# NUC029AN_v1 register map
File version: 1.0
Registers are 32-bit, read-write, reset 0x0 unless marked. A register's access mark holds for its fields unless they carry their own. Offsets are from the block's base; [hi:lo] are bit positions; {n}, {i} and the like mark numbered series; 'fields as' and 'values as' point back to an identical list.

## CLK — CLK Register Map
Base 0x50000200
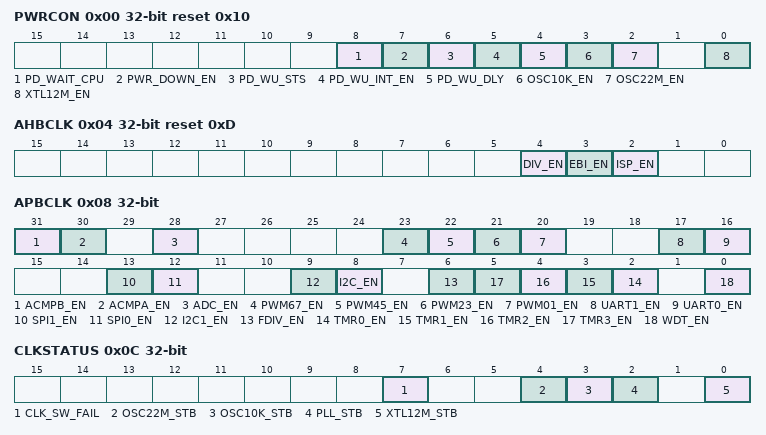
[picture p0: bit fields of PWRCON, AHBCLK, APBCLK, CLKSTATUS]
0x00 PWRCON reset 0x10 (reset mask 0xFFFFFFF0) — System Power Down Control Register
  [8] PD_WAIT_CPU — This bit control the power down entry condition (write-protected)
    0=Chip entry power down mode when the PWR_DOWN_EN bit is set to 1; 1=Chip enter power down mode when the both PWR_DOWN_EN bit is set to 1 and CPU run WFI instruction
  [7] PWR_DOWN_EN — System power down enable bit (write-protected). When CPU sets this bit "1" the chip power down mode is enabled, and chip power-down behavior will depends on the PD_WAIT_CPU bit (a) If the PD_WAIT_CPU is "0", then the chip enters power down mode immediately after the PWR_DOWN_EN bit set. (b) if the PD_WAIT_CPU is "1", then the chip keeps active till the CPU sleep mode is also active and then the chip enters power down mode. When chip wakes up from power down mode, this bit is auto cleared. Users need to set this bit again for next power down. When in power down mode, external crystal (4~ 24MHz) and the 22.1184 MHz OSC will be disabled in this mode, but the 10 kHz OSC is not controlled by power down mode. When in power down mode, the PLL and system clock are disabled, and ignored the clock source selection. The clocks of peripheral are not controlled by power down mode, if the peripheral clock source is from 10 kHz oscillator.
    0=Chip operate in normal mode or CPU in idle mode (sleep mode) because of WFI command; 1=Chip enter the power down mode instant or wait CPU sleep command WFI
  [6] PD_WU_STS — Power down mode wake up interrupt status. Set by "power down wake up event", it indicates that resume from power down mode" The flag is set if the GPIO, UART, WDT, ACMPA, ACMPB , I2C, TIMER, or BOD wakeup occurred. Write 1 to clear the bit to zero. Note: This bit is working only if PD_WU_INT_EN (PWRCON[5]) set to 1.
  [5] PD_WU_INT_EN — Power down mode wake Up Interrupt Enable (write-protected). The interrupt will occur when both PD_WU_STS and PD_WU_INT_EN are high.
    0=Disable; 1=Enable
  [4] PD_WU_DLY — Enable the wake up delay counter. (write-protected). When the chip wakes up from power down mode, the clock control will delay certain clock cycles to wait system clock stable. The delayed clock cycle is 4096 clock cycles when chip work at external crystal (4 ~ 24MHz), and 256 clock cycles when chip work at 22.1184 MHz oscillator.
    0=Disable clock cycles delay; 1=Enable clock cycles delay
  [3] OSC10K_EN — Internal 10 kHz Oscillator enable (write-protected)
    0=10 kHz Oscillation disable; 1=10 kHz Oscillation enable
  [2] OSC22M_EN — Internal 22.1184 MHz Oscillator enable (write-protected)
    0=22.1184 MHz Oscillation disable; 1=22.1184 MHz Oscillation enable
  [0] XTL12M_EN — External Crystal Oscillator enable (write-protected). The bit default value is set by flash controller user configuration register config0 [26:24]. When the default clock source is from external crystal, the bit is automatically set to "1"
    0=Crystal oscillation disable; 1=Crystal oscillation enable
0x04 AHBCLK reset 0xD — AHB Devices Clock Enable Control Register
  [4] DIV_EN — Hardware Divider Controller Clock Enable Control
    0=Hardware Divider engine clock Disabled; 1=Hardware Divider engine clock Enabled
  [3] EBI_EN — EBI Controller Clock Enable Control.
    0=Disable the EBI controller clock; 1=Enable the EBI controller clock
  [2] ISP_EN — Flash ISP Controller Clock Enable Control.
    0=To disable the Flash ISP controller clock; 1=To enable the Flash ISP controller clock
0x08 APBCLK (reset mask 0xFFFFFFF0) — APB Devices Clock Enable Control Register
  [31] ACMPB_EN — Analog Comparator B Clock Enable
    0=Disable the Analog Comparator B Clock; 1=Enable the Analog Comparator B Clock
  [30] ACMPA_EN — Analog Comparator A Clock Enable
    0=Disable the Analog Comparator A Clock; 1=Enable the Analog Comparator A Clock
  [28] ADC_EN — Analog-Digital-Converter (ADC) Clock Enable
    0=Disable ADC clock; 1=Enable ADC clock
  [23] PWM67_EN — PWM_67 Clock Enable
    0=Disable PWM67 clock; 1=Enable PWM67 clock
  [22] PWM45_EN — PWM_45 Clock Enable
    0=Disable PWM45 clock; 1=Enable PWM45 clock
  [21] PWM23_EN — PWM_23 Clock Enable
    0=Disable PWM23 clock; 1=Enable PWM23 clock
  [20] PWM01_EN — PWM_01 Clock Enable
    0=Disable PWM01 clock; 1=Enable PWM01 clock
  [17] UART1_EN — UART1 Clock Enable
    0=Disable UART1 clock; 1=Enable UART1 clock
  [16] UART0_EN — UART0 Clock Enable
    0=Disable UART0 clock; 1=Enable UART0 clock
  [13] SPI1_EN — SPI1 Clock Enable
    0=Disable SPI1 Clock; 1=Enable SPI1 Clock
  [12] SPI0_EN — SPI0 Clock Enable
    0=Disable SPI0 Clock; 1=Enable SPI0 Clock
  [9] I2C1_EN — I2C1 Clock Enable
    0=Disable I2C1 Clock; 1=Enable I2C1 Clock
  [8] I2C_EN — I2C0 Clock Enable
    0=Disable I2C0 Clock; 1=Enable I2C0 Clock
  [6] FDIV_EN — Clock Divider Clock Enable
    0=Disable FDIV Clock; 1=Enable FDIV Clock
  [n+2] TMR{n}_EN (n=0..3) — Timer{n} Clock Enable
    0=Disable Timer{n} Clock; 1=Enable Timer{n} Clock
  [0] WDT_EN — Watchdog Timer Clock Enable (write-protected)
    0=Disable Watchdog Timer Clock; 1=Enable Watchdog Timer Clock
0x0C CLKSTATUS (reset mask 0xFFFFFF00) — Clock status monitor Register
  [7] CLK_SW_FAIL — Clock Switching Fail Flag. This bit is updated when software switches system clock source. If switch target clock is stable, this bit will be set to 0. If switch target clock is not stable, this bit will be set to 1. Write 1 to clear the bit to 0.
    0=Clock switching success; 1=Clock switching failed
  [4] OSC22M_STB ro — OSC22M (Internal 22.1184 MHz) clock source stable flag (Read Only)
    0=OSC22M clock is not stable or disable; 1=OSC22M clock is stable
  [3] OSC10K_STB ro — OSC10K clock source stable flag (Read Only)
    0=OSC10K clock is not stable or disable; 1=OSC10K clock is stable
  [2] PLL_STB ro — PLL clock source stable flag (Read Only)
    0=PLL clock is not stable or disable; 1=PLL clock is stable
  [0] XTL12M_STB ro — External Crystal clock source stable flag (Read Only)
    0=External Crystal clock is not stable or disable; 1=External Crystal clock is stable
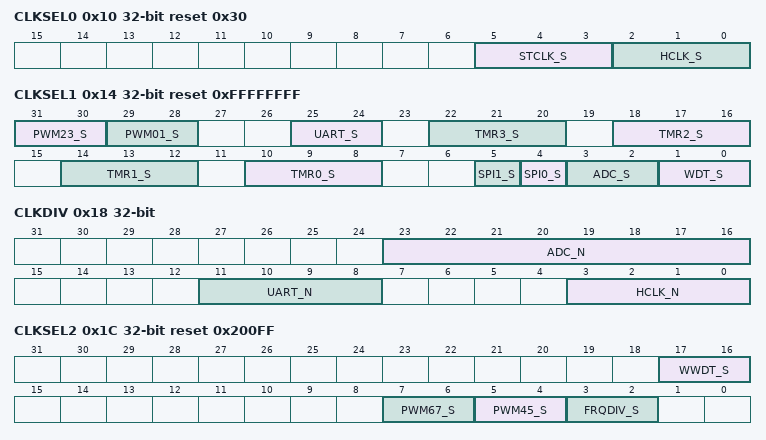
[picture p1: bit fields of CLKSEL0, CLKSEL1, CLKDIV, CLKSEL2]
0x10 CLKSEL0 reset 0x30 (reset mask 0xFFFFFFF0) — Clock Source Select Control Register 0
  [5:3] STCLK_S — Cortex-M0 SysTick Clock Source Select (write-protected)
    0=Clock source from external 4~24 MHz high speed crystal clock; 2=Clock source from external 4~24 MHz high speed crystal clock/2; 3=Clock source from HCLK/2; 7=Clock source from internal 22.1184 MHz high speed oscillator clock/2
  [2:0] HCLK_S — HCLK Clock Source Select (Write-protection Bits). Before clock switching, the related clock sources (both pre-select and new-select) must be turn on. The 3-bit default value is reloaded from the value of CFOSC (CONFIG [26:24]) in user configuration register of Flash controller by any reset. Therefore the default value is either 000b or 111b. These bits are protected bit. It means programming them needs to write "59h", "16h", and "88h" to address 0x5000_0100 to disable register protection. Refer to the register REGWRPROT at address GCR_BA+0x100.
    0=Clock source from external 4~24 MHz high speed crystal oscillator clock; 2=Clock source from PLL clock; 3=Clock source from internal 10 kHz low speed oscillator clock; 7=Clock source from internal 22.1184 MHz high speed oscillator clock
0x14 CLKSEL1 reset 0xFFFFFFFF — Clock Source Select Control Register 1
  [31:30] PWM23_S — PWM2 and PWM3 clock source select. PWM2 and PWM3 uses the same Engine clock source, both of them use the same pre-scalar
    0=Clock source from external crystal clock (4 ~ 24MHz); 1=Clock source from internal 10 kHz low speed oscillator clock; 2=Clock source from HCLK; 3=Clock source from internal 22.1184 MHz oscillator clock
  [29:28] PWM01_S — PWM0 and PWM1 clock source select. PWM0 and PWM1 uses the same Engine clock source, both of them use the same pre-scalar
    0=Clock source from external crystal clock ( 4 ~ 24MHz); 1=Clock source from internal 10 kHz low speed oscillator clock; 2=Clock source from HCLK; 3=Clock source from internal 22.1184 MHz oscillator clock
  [25:24] UART_S — UART clock source select.
    0=Clock source from external crystal clock (4 ~ 24MHz); 1=Clock source from PLL clock; 3=Clock source from internal 22.1184 MHz oscillator clock
  [22:20] TMR3_S — TIMER3 clock source select.
    0=Clock source from external crystal clock (4 ~ 24MHz); 2=Clock source from HCLK; 3=Clock source from external trigger T3; 5=Clock source from internal 10 kHz low speed oscillator clock; 7=Clock source from internal 22.1184 MHz oscillator clock
  [18:16] TMR2_S — TIMER2 clock source select.
    0=Clock source from external crystal clock (4 ~ 24MHz); 2=Clock source from HCLK; 3=Clock source from external trigger T2; 5=Clock source from internal 10 kHz low speed oscillator clock; 7=Clock source from internal 22.1184 MHz oscillator clock
  [14:12] TMR1_S — TIMER1 clock source select.
    0=Clock source from external crystal clock (4 ~ 24MHz); 2=Clock source from HCLK; 3=Clock source from external trigger T1; 5=Clock source from internal 10 kHz low speed oscillator clock; 7=Clock source from internal 22.1184 MHz oscillator clock
  [10:8] TMR0_S — TIMER0 clock source select.
    0=Clock source from external crystal clock (4 ~ 24 MHz); 2=Clock source from HCLK; 3=Clock source from external trigger T0; 5=Clock source from internal 10 kHz low speed oscillator clock; 7=Clock source from internal 22.1184 MHz oscillator clock
  [5] SPI1_S — SPI1 clock source select
    0=Clock source from PLL clock; 1=Clock source from HCLK
  [4] SPI0_S — SPI0 clock source select
    0=Clock source from PLL clock; 1=Clock source from HCLK
  [3:2] ADC_S — ADC clock source select
    0=Clock source from external crystal clock (4 ~ 24MHz); 1=Clock source from PLL clock; 2=Clock source from HCLK; 3=Clock source from internal 22.1184 MHz oscillator clock
  [1:0] WDT_S — WDT clock source select (write-protected)
    2=Clock source from HCLK/2048 clock; 3=Clock source from internal 10 kHz oscillator clock
0x18 CLKDIV — Clock Divider Number Register
  [23:16] ADC_N — ADC clock divide number from ADC clock source
  [11:8] UART_N — UART clock divide number from UART clock source
  [3:0] HCLK_N — HCLK clock divide number from HCLK clock source
0x1C CLKSEL2 reset 0x200FF — Clock Source Select Control Register 2
  [17:16] WWDT_S — Window Watchdog Timer clock source select
    2=Clock source from HCLK/2048 clock; 3=Clock source from internal 10 kHz low speed oscillator clock
  [7:6] PWM67_S — PWM6 and PWM7 clock source select. PWM6 and PWM7 used the same Engine clock source, both of them use the same pre-scalar
    values as CLKSEL1.PWM23_S
  [5:4] PWM45_S — PWM4 and PWM5 clock source select. PWM4 and PWM5 used the same Engine clock source, both of them use the same pre-scalar
    0=Clock source from external crystal clock (4 ~ 24 MHz); 1=Clock source from internal 10 kHz low speed oscillator clock; 2=Clock source from HCLK; 3=Clock source from internal 22.1184 MHz oscillator clock
  [3:2] FRQDIV_S — Clock Divider Clock Source Select
    0=Clock source from external crystal clock (4 ~ 24 MHz); 2=Clock source from HCLK; 3=Clock source from internal 22.1184 MHz oscillator clock
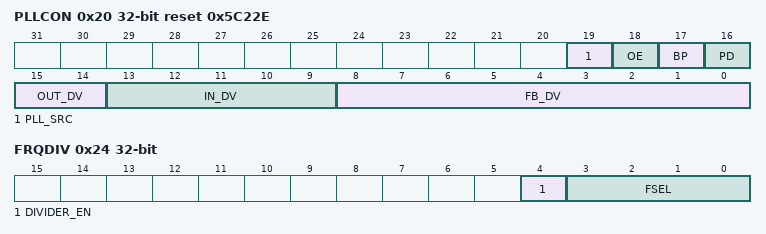
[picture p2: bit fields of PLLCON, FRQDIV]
0x20 PLLCON reset 0x5C22E — PLL Control Register
  [19] PLL_SRC — PLL Source Clock Select
    0=PLL source clock from external crystal (4 ~ 24 MHz); 1=PLL source clock from 22.1184 MHz oscillator
  [18] OE — PLL OE (FOUT enable) pin Control
    0=PLL FOUT enable; 1=PLL FOUT is fixed low
  [17] BP — PLL Bypass Control
    0=PLL is in Normal mode (default); 1=PLL clock output is same as PLL source clock input
  [16] PD — Power down Mode. If the PWR_DOWN_EN bit is set to 1 in PWRCON register, the PLL will enter Power-down mode too.
    0=PLL is in Normal mode; 1=PLL is in Power-down mode (default)
  [15:14] OUT_DV — PLL Output Divider Control
  [13:9] IN_DV — PLL Input Divider Control
  [8:0] FB_DV — PLL Feedback Divider Control
0x24 FRQDIV — Frequency Divider Control Register
  [4] DIVIDER_EN — Frequency Divider Enable Bit
    0=Disable Frequency Divider; 1=Enable Frequency Divider
  [3:0] FSEL — Divider Output Frequency Selection Bits. The formula of output frequency is. Fin is the input clock frequency. Fout is the frequency of divider output clock. N is the 4-bit value of FSEL[3:0].
